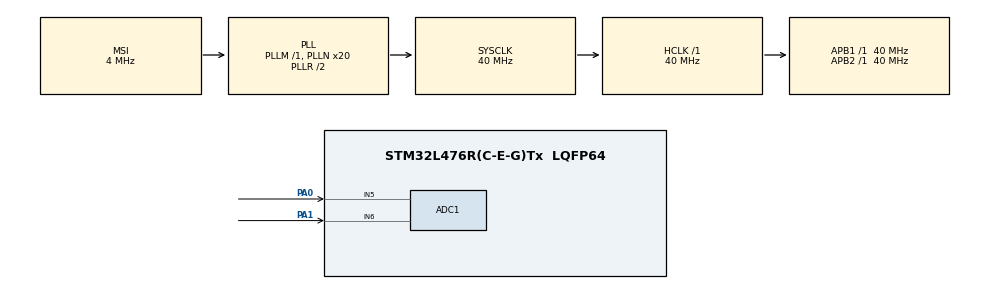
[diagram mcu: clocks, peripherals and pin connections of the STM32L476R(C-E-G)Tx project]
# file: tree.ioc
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ADC1.Channel-0\#ChannelRegularConversion=ADC_CHANNEL_5
ADC1.NbrOfConversionFlag=1
ADC1.OffsetNumber-0\#ChannelRegularConversion=ADC_OFFSET_NONE
ADC1.Rank-0\#ChannelRegularConversion=1
ADC1.SamplingTime-0\#ChannelRegularConversion=ADC_SAMPLETIME_2CYCLES_5
ADC1.master=1
Mcu.Family=STM32L4
Mcu.Name=STM32L476R(C-E-G)Tx
Mcu.Package=LQFP64
NVIC.PriorityGroup=NVIC_PRIORITYGROUP_4
PA0.Signal=ADCx_IN5
PA1.Signal=ADCx_IN6
ProjectManager.HeapSize=0x200
ProjectManager.StackSize=0x400
ProjectManager.TargetToolchain=MDK-ARM V5
RCC.ADCFreq_Value=32000000
RCC.AHBFreq_Value=40000000
RCC.APB1Freq_Value=40000000
RCC.APB1TimFreq_Value=40000000
RCC.APB2Freq_Value=40000000
RCC.APB2TimFreq_Value=40000000
RCC.CortexFreq_Value=40000000
RCC.HCLKFreq_Value=40000000
RCC.HSE_VALUE=8000000
RCC.HSI_VALUE=16000000
RCC.LSE_VALUE=32768
RCC.MSI_VALUE=4000000
RCC.PLLN=20
RCC.PLLSAI1N=16
RCC.SYSCLKFreq_VALUE=40000000
RCC.SYSCLKSource=RCC_SYSCLKSOURCE_PLLCLK
RCC.USBFreq_Value=32000000
RCC.VCOOutputFreq_Value=80000000
SH.ADCx_IN5.0=ADC1_IN5,IN5-Single-Ended
SH.ADCx_IN6.0=ADC1_IN6,IN6-Single-Ended
board=tree

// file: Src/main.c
/**
  ******************************************************************************
  * File Name          : main.c
  * Description        : Main program body
  ******************************************************************************
  ** This notice applies to any and all portions of this file
  * that are not between comment pairs USER CODE BEGIN and
  * USER CODE END. Other portions of this file, whether
  * inserted by the user or by software development tools
  * are owned by their respective copyright owners.
  *
  * COPYRIGHT(c) 2018 STMicroelectronics
  *
  * Redistribution and use in source and binary forms, with or without modification,
  * are permitted provided that the following conditions are met:
  *   1. Redistributions of source code must retain the above copyright notice,
  *      this list of conditions and the following disclaimer.
  *   2. Redistributions in binary form must reproduce the above copyright notice,
  *      this list of conditions and the following disclaimer in the documentation
  *      and/or other materials provided with the distribution.
  *   3. Neither the name of STMicroelectronics nor the names of its contributors
  *      may be used to endorse or promote products derived from this software
  *      without specific prior written permission.
  *
  * THIS SOFTWARE IS PROVIDED BY THE COPYRIGHT HOLDERS AND CONTRIBUTORS "AS IS"
  * AND ANY EXPRESS OR IMPLIED WARRANTIES, INCLUDING, BUT NOT LIMITED TO, THE
  * IMPLIED WARRANTIES OF MERCHANTABILITY AND FITNESS FOR A PARTICULAR PURPOSE ARE
  * DISCLAIMED. IN NO EVENT SHALL THE COPYRIGHT HOLDER OR CONTRIBUTORS BE LIABLE
  * FOR ANY DIRECT, INDIRECT, INCIDENTAL, SPECIAL, EXEMPLARY, OR CONSEQUENTIAL
  * DAMAGES (INCLUDING, BUT NOT LIMITED TO, PROCUREMENT OF SUBSTITUTE GOODS OR
  * SERVICES; LOSS OF USE, DATA, OR PROFITS; OR BUSINESS INTERRUPTION) HOWEVER
  * CAUSED AND ON ANY THEORY OF LIABILITY, WHETHER IN CONTRACT, STRICT LIABILITY,
  * OR TORT (INCLUDING NEGLIGENCE OR OTHERWISE) ARISING IN ANY WAY OUT OF THE USE
  * OF THIS SOFTWARE, EVEN IF ADVISED OF THE POSSIBILITY OF SUCH DAMAGE.
  *
  ******************************************************************************
  */

#include "main.h"
#include "stm32l4xx_hal.h"
#include "arm_math.h"
#include "stm32l476xx.h"
/* USER CODE BEGIN Includes */
#define FFT_SIZE 256
//#define ARM_MATH_CM4
/* USER CODE END Includes */
ADC_HandleTypeDef hadc1;
q15_t fft_Sbuff[FFT_SIZE] = {0};
q15_t fft_Dbuff[FFT_SIZE*2] = {0};
uint16_t k;
uint8_t status;
arm_rfft_instance_q15 S;
ADC_HandleTypeDef hadc1;

/* USER CODE BEGIN PV */
/* Private variables ---------------------------------------------------------*/

/* USER CODE END PV */

void SystemClock_Config(void);
static void MX_GPIO_Init(void);
static void MX_ADC1_Init(void);

/* USER CODE BEGIN PFP */
/* Private function prototypes -----------------------------------------------*/

/* USER CODE END PFP */

int main(void)
{

  /* MCU Configuration----------------------------------------------------------*/

  /* Reset of all peripherals, Initializes the Flash interface and the Systick. */
  HAL_Init();

  /* Configure the system clock */
  SystemClock_Config();

  /* Initialize all configured peripherals */
  MX_GPIO_Init();
  MX_ADC1_Init();

  /* Infinite loop */
	status = arm_rfft_init_q15(&S, FFT_SIZE, 0, 1);
if(status == ARM_MATH_SUCCESS)
{
    arm_rfft_q15(&S,fft_Sbuff, fft_Dbuff);
    arm_cmplx_mag_q15( fft_Sbuff,fft_Dbuff, FFT_SIZE);
}
  while (1)
  {

  }

}

/** System Clock Configuration
*/
void SystemClock_Config(void)
{

  RCC_OscInitTypeDef RCC_OscInitStruct;
  RCC_ClkInitTypeDef RCC_ClkInitStruct;
  RCC_PeriphCLKInitTypeDef PeriphClkInit;

    /**Initializes the CPU, AHB and APB busses clocks
    */
  RCC_OscInitStruct.OscillatorType = RCC_OSCILLATORTYPE_MSI;
  RCC_OscInitStruct.MSIState = RCC_MSI_ON;
  RCC_OscInitStruct.MSICalibrationValue = 0;
  RCC_OscInitStruct.MSIClockRange = RCC_MSIRANGE_6;
  RCC_OscInitStruct.PLL.PLLState = RCC_PLL_ON;
  RCC_OscInitStruct.PLL.PLLSource = RCC_PLLSOURCE_MSI;
  RCC_OscInitStruct.PLL.PLLM = 1;
  RCC_OscInitStruct.PLL.PLLN = 20;
  RCC_OscInitStruct.PLL.PLLP = RCC_PLLP_DIV7;
  RCC_OscInitStruct.PLL.PLLQ = RCC_PLLQ_DIV2;
  RCC_OscInitStruct.PLL.PLLR = RCC_PLLR_DIV2;
  if (HAL_RCC_OscConfig(&RCC_OscInitStruct) != HAL_OK)
  {
    _Error_Handler(__FILE__, __LINE__);
  }

    /**Initializes the CPU, AHB and APB busses clocks
    */
  RCC_ClkInitStruct.ClockType = RCC_CLOCKTYPE_HCLK|RCC_CLOCKTYPE_SYSCLK
                              |RCC_CLOCKTYPE_PCLK1|RCC_CLOCKTYPE_PCLK2;
  RCC_ClkInitStruct.SYSCLKSource = RCC_SYSCLKSOURCE_PLLCLK;
  RCC_ClkInitStruct.AHBCLKDivider = RCC_SYSCLK_DIV1;
  RCC_ClkInitStruct.APB1CLKDivider = RCC_HCLK_DIV1;
  RCC_ClkInitStruct.APB2CLKDivider = RCC_HCLK_DIV1;

  if (HAL_RCC_ClockConfig(&RCC_ClkInitStruct, FLASH_LATENCY_1) != HAL_OK)
  {
    _Error_Handler(__FILE__, __LINE__);
  }

  PeriphClkInit.PeriphClockSelection = RCC_PERIPHCLK_ADC;
  PeriphClkInit.AdcClockSelection = RCC_ADCCLKSOURCE_PLLSAI1;
  PeriphClkInit.PLLSAI1.PLLSAI1Source = RCC_PLLSOURCE_MSI;
  PeriphClkInit.PLLSAI1.PLLSAI1M = 1;
  PeriphClkInit.PLLSAI1.PLLSAI1N = 16;
  PeriphClkInit.PLLSAI1.PLLSAI1P = RCC_PLLP_DIV7;
  PeriphClkInit.PLLSAI1.PLLSAI1Q = RCC_PLLQ_DIV2;
  PeriphClkInit.PLLSAI1.PLLSAI1R = RCC_PLLR_DIV2;
  PeriphClkInit.PLLSAI1.PLLSAI1ClockOut = RCC_PLLSAI1_ADC1CLK;
  if (HAL_RCCEx_PeriphCLKConfig(&PeriphClkInit) != HAL_OK)
  {
    _Error_Handler(__FILE__, __LINE__);
  }

    /**Configure the main internal regulator output voltage
    */
  if (HAL_PWREx_ControlVoltageScaling(PWR_REGULATOR_VOLTAGE_SCALE1) != HAL_OK)
  {
    _Error_Handler(__FILE__, __LINE__);
  }

    /**Configure the Systick interrupt time
    */
  HAL_SYSTICK_Config(HAL_RCC_GetHCLKFreq()/1000);

    /**Configure the Systick
    */
  HAL_SYSTICK_CLKSourceConfig(SYSTICK_CLKSOURCE_HCLK);

  /* SysTick_IRQn interrupt configuration */
  HAL_NVIC_SetPriority(SysTick_IRQn, 0, 0);
}

/* ADC1 init function */
static void MX_ADC1_Init(void)
{

  ADC_MultiModeTypeDef multimode;
  ADC_ChannelConfTypeDef sConfig;

    /**Common config
    */
  hadc1.Instance = ADC1;
  hadc1.Init.ClockPrescaler = ADC_CLOCK_ASYNC_DIV1;
  hadc1.Init.Resolution = ADC_RESOLUTION_12B;
  hadc1.Init.DataAlign = ADC_DATAALIGN_RIGHT;
  hadc1.Init.ScanConvMode = ADC_SCAN_DISABLE;
  hadc1.Init.EOCSelection = ADC_EOC_SINGLE_CONV;
  hadc1.Init.LowPowerAutoWait = DISABLE;
  hadc1.Init.ContinuousConvMode = DISABLE;
  hadc1.Init.NbrOfConversion = 1;
  hadc1.Init.DiscontinuousConvMode = DISABLE;
  hadc1.Init.NbrOfDiscConversion = 1;
  hadc1.Init.ExternalTrigConv = ADC_SOFTWARE_START;
  hadc1.Init.ExternalTrigConvEdge = ADC_EXTERNALTRIGCONVEDGE_NONE;
  hadc1.Init.DMAContinuousRequests = DISABLE;
  hadc1.Init.Overrun = ADC_OVR_DATA_PRESERVED;
  hadc1.Init.OversamplingMode = DISABLE;
  if (HAL_ADC_Init(&hadc1) != HAL_OK)
  {
    _Error_Handler(__FILE__, __LINE__);
  }

    /**Configure the ADC multi-mode
    */
  multimode.Mode = ADC_MODE_INDEPENDENT;
  if (HAL_ADCEx_MultiModeConfigChannel(&hadc1, &multimode) != HAL_OK)
  {
    _Error_Handler(__FILE__, __LINE__);
  }

    /**Configure Regular Channel
    */
  sConfig.Channel = ADC_CHANNEL_5;
  sConfig.Rank = 1;
  sConfig.SamplingTime = ADC_SAMPLETIME_2CYCLES_5;
  sConfig.SingleDiff = ADC_SINGLE_ENDED;
  sConfig.OffsetNumber = ADC_OFFSET_NONE;
  sConfig.Offset = 0;
  if (HAL_ADC_ConfigChannel(&hadc1, &sConfig) != HAL_OK)
  {
    _Error_Handler(__FILE__, __LINE__);
  }

}

/** Pinout Configuration
*/
static void MX_GPIO_Init(void)
{

  /* GPIO Ports Clock Enable */
  __HAL_RCC_GPIOA_CLK_ENABLE();

}

void _Error_Handler(char * file, int line)
{
  while(1)
  {
  }
}

/************************ (C) COPYRIGHT STMicroelectronics *****END OF FILE****/
